AUTOSAR XML (schema 00046)
package /ComponentTypes
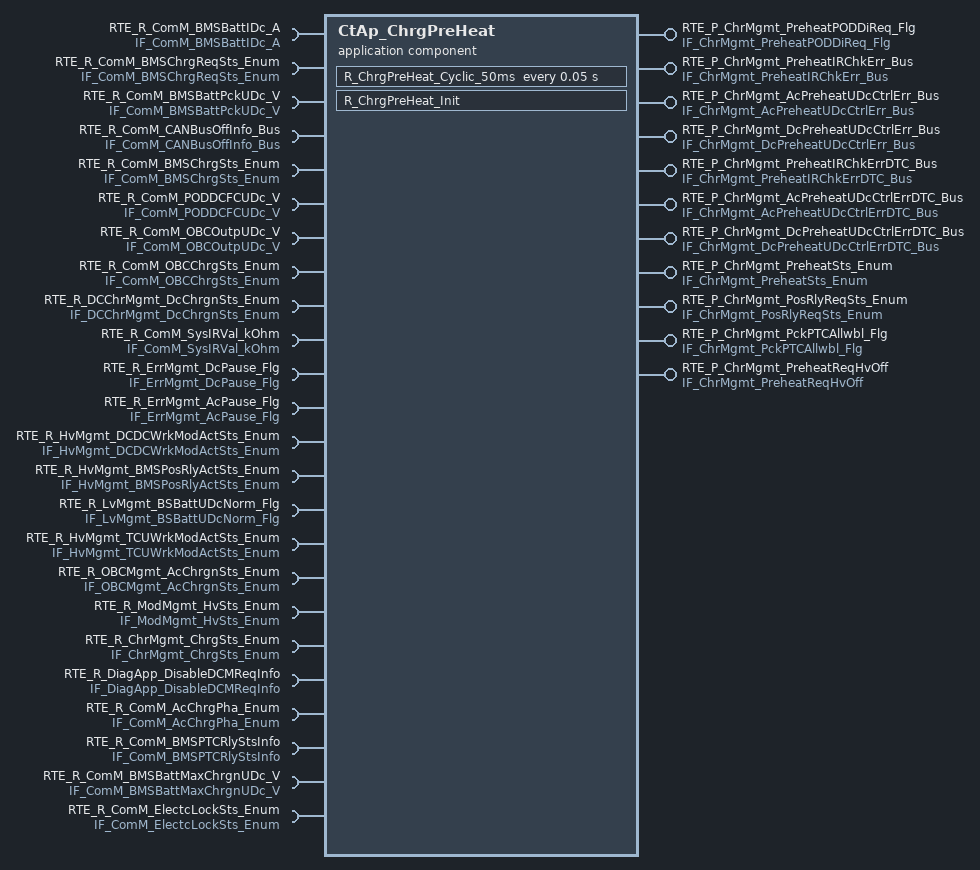
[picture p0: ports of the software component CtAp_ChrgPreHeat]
  application sw component type CtAp_ChrgPreHeat
    7 x provide port:
      RTE_P_ChrMgmt_PreheatPODDiReq_Flg: nonqueued-sender-com-spec{data-element=tec_ChrMgmt_PreheatPODDiReq_Flg, init-value=0}, provided-interface=IF_ChrMgmt_PreheatPODDiReq_Flg
      RTE_P_ChrMgmt_PreheatIRChkErr_Bus: nonqueued-sender-com-spec{data-element=tec_ChrMgmt_PreheatIRChkErr_Bus, init-value=fields=[ChrMgmt_MonStatPreheatIRChkErr:0, ChrMgmt_MonResPreheatIRChkErr:0, ChrMgmt_ErrStatPreheatIRChkErr:0, ChrMgmt_ErrResPreheatIRChkErr:0]}, provided-interface=IF_ChrMgmt_PreheatIRChkErr_Bus
      RTE_P_ChrMgmt_AcPreheatUDcCtrlErr_Bus: nonqueued-sender-com-spec{data-element=tec_ChrMgmt_AcPreheatUDcCtrlErr_Bus, init-value=fields=[ChrMgmt_MonStatAcPreheatUDcCtrlErr:0, ChrMgmt_MonResAcPreheatUDcCtrlErr:0, ChrMgmt_ErrStatAcPreheatUDcCtrlErr:0, ChrMgmt_ErrResAcPreheatUDcCtrlErr:0]}, provided-interface=IF_ChrMgmt_AcPreheatUDcCtrlErr_Bus
      RTE_P_ChrMgmt_DcPreheatUDcCtrlErr_Bus: nonqueued-sender-com-spec{data-element=tec_ChrMgmt_DcPreheatUDcCtrlErr_Bus, init-value=fields=[ChrMgmt_MonStatDcPreheatUDcCtrlErr:0, ChrMgmt_MonResDcPreheatUDcCtrlErr:0, ChrMgmt_ErrStatDcPreheatUDcCtrlErr:0, ChrMgmt_ErrResDcPreheatUDcCtrlErr:0]}, provided-interface=IF_ChrMgmt_DcPreheatUDcCtrlErr_Bus
      RTE_P_ChrMgmt_PreheatIRChkErrDTC_Bus: nonqueued-sender-com-spec{data-element=tec_ChrMgmt_PreheatIRChkErrDTC_Bus, init-value=fields=[ChrMgmt_MonStatPreheatIRChkErrDTC:0, ChrMgmt_MonResPreheatIRChkErrDTC:0, ChrMgmt_ErrStatPreheatIRChkErrDTC:0, ChrMgmt_ErrResPreheatIRChkErrDTC:0]}, provided-interface=IF_ChrMgmt_PreheatIRChkErrDTC_Bus
      RTE_P_ChrMgmt_AcPreheatUDcCtrlErrDTC_Bus: nonqueued-sender-com-spec{data-element=tec_ChrMgmt_AcPreheatUDcCtrlErrDTC_Bus, init-value=fields=[ChrMgmt_MonStatAcPreheatUDcCtrlErrDTC:0, ChrMgmt_MonResAcPreheatUDcCtrlErrDTC:0, ChrMgmt_ErrStatAcPreheatUDcCtrlErrDTC:0, ChrMgmt_ErrResAcPreheatUDcCtrlErrDTC:0]}, provided-interface=IF_ChrMgmt_AcPreheatUDcCtrlErrDTC_Bus
      RTE_P_ChrMgmt_DcPreheatUDcCtrlErrDTC_Bus: nonqueued-sender-com-spec{data-element=tec_ChrMgmt_DcPreheatUDcCtrlErrDTC_Bus, init-value=fields=[ChrMgmt_MonStatDcPreheatUDcCtrlErrDTC:0, ChrMgmt_MonResDcPreheatUDcCtrlErrDTC:0, ChrMgmt_ErrStatDcPreheatUDcCtrlErrDTC:0, ChrMgmt_ErrResDcPreheatUDcCtrlErrDTC:0]}, provided-interface=IF_ChrMgmt_DcPreheatUDcCtrlErrDTC_Bus
    18 x require port:
      RTE_R_ComM_BMSBattIDc_A: nonqueued-receiver-com-spec{data-element=tec_ComM_BMSBattIDc_A, filter=data-filter-type=ALWAYS, init-value=0}, required-interface=IF_ComM_BMSBattIDc_A
      RTE_R_ComM_BMSChrgReqSts_Enum: nonqueued-receiver-com-spec{data-element=tec_ComM_BMSChrgReqSts_Enum, filter=data-filter-type=ALWAYS, init-value=0}, required-interface=IF_ComM_BMSChrgReqSts_Enum
      RTE_R_ComM_BMSBattPckUDc_V: nonqueued-receiver-com-spec{data-element=tec_ComM_BMSBattPckUDc_V, filter=data-filter-type=ALWAYS, init-value=0}, required-interface=IF_ComM_BMSBattPckUDc_V
      RTE_R_ComM_CANBusOffInfo_Bus: required-interface=IF_ComM_CANBusOffInfo_Bus
        required-com-specs:
          data-element=tec_ComM_EPTCANBusOffInfo_Bus, filter=data-filter-type=ALWAYS, init-value=fields=[ComM_MonStatEPTCANBusOffInfo:0, ComM_MonResEPTCANBusOffInfo:0, ComM_ErrStatEPTCANBusOffInfo:0, ComM_ErrResEPTCANBusOffInfo:0]
          data-element=tec_ComM_CHCANBusOffInfo_Bus, filter=data-filter-type=ALWAYS, init-value=fields=[ComM_MonStatCHCANBusOffInfo:0, ComM_MonResCHCANBusOffInfo:0, ComM_ErrStatCHCANBusOffInfo:0, ComM_ErrResCHCANBusOffInfo:0]
          data-element=tec_ComM_EPTCANBusOffDTCInfo_Bus, filter=data-filter-type=ALWAYS, init-value=fields=[ComM_MonStatEPTCANBusOffDTCInfo:0, ComM_MonResEPTCANBusOffDTCInfo:0, ComM_ErrStatEPTCANBusOffDTCInfo:0, ComM_ErrResEPTCANBusOffDTCInfo:0]
          data-element=tec_ComM_CHCANBusOffDTCInfo_Bus, filter=data-filter-type=ALWAYS, init-value=fields=[ComM_MonStatCHCANBusOffDTCInfo:0, ComM_MonResCHCANBusOffDTCInfo:0, ComM_ErrStatCHCANBusOffDTCInfo:0, ComM_ErrResCHCANBusOffDTCInfo:0]
          data-element=tec_ComM_DCCANBusOffDTCInfo_Bus, init-value=fields=[ComM_MonStatDCCANDTCBusOffInfo:0, ComM_MonResDCCANDTCBusOffInfo:0, ComM_ErrStatDCCANDTCBusOffInfo:0, ComM_ErrResDCCANDTCBusOffInfo:0]
          data-element=tec_ComM_DCCANBusOffInfo_Bus, init-value=fields=[ComM_MonStatDCCANBusOffInfo:0, ComM_MonResDCCANBusOffInfo:0, ComM_ErrStatDCCANBusOffInfo:0, ComM_ErrResDCCANBusOffInfo:0]
      RTE_R_ComM_BMSChrgSts_Enum: nonqueued-receiver-com-spec{data-element=tec_ComM_BMSChrgSts_Enum, filter=data-filter-type=ALWAYS, init-value=0}, required-interface=IF_ComM_BMSChrgSts_Enum
      RTE_R_ComM_PODDCFCUDc_V: nonqueued-receiver-com-spec{data-element=tec_ComM_PODDCFCUDc_V, filter=data-filter-type=ALWAYS, init-value=0}, required-interface=IF_ComM_PODDCFCUDc_V
      RTE_R_ComM_OBCOutpUDc_V: nonqueued-receiver-com-spec{data-element=tec_ComM_OBCOutpUDc_V, filter=data-filter-type=ALWAYS, init-value=0}, required-interface=IF_ComM_OBCOutpUDc_V
      RTE_R_ComM_OBCChrgSts_Enum: nonqueued-receiver-com-spec{data-element=tec_ComM_OBCChrgSts_Enum, filter=data-filter-type=ALWAYS, init-value=0}, required-interface=IF_ComM_OBCChrgSts_Enum
      RTE_R_DCChrMgmt_DcChrgnSts_Enum: nonqueued-receiver-com-spec{data-element=tec_DCChrMgmt_DcChrgnSts_Enum, filter=data-filter-type=ALWAYS, init-value=0}, required-interface=IF_DCChrMgmt_DcChrgnSts_Enum
      RTE_R_ComM_SysIRVal_kOhm: nonqueued-receiver-com-spec{data-element=tec_ComM_SysIRVal_kOhm, filter=data-filter-type=ALWAYS, init-value=0}, required-interface=IF_ComM_SysIRVal_kOhm
      RTE_R_ErrMgmt_DcPause_Flg: nonqueued-receiver-com-spec{data-element=tec_ErrMgmt_DcPause_Flg, filter=data-filter-type=ALWAYS, init-value=0}, required-interface=IF_ErrMgmt_DcPause_Flg
      RTE_R_ErrMgmt_AcPause_Flg: nonqueued-receiver-com-spec{data-element=tec_ErrMgmt_AcPause_Flg, filter=data-filter-type=ALWAYS, init-value=0}, required-interface=IF_ErrMgmt_AcPause_Flg
      RTE_R_HvMgmt_DCDCWrkModActSts_Enum: nonqueued-receiver-com-spec{data-element=tec_HvMgmt_DCDCWrkModActSts_Enum, filter=data-filter-type=ALWAYS, init-value=0}, required-interface=IF_HvMgmt_DCDCWrkModActSts_Enum
      RTE_R_HvMgmt_BMSPosRlyActSts_Enum: nonqueued-receiver-com-spec{data-element=tec_HvMgmt_BMSPosRlyActSts_Enum, filter=data-filter-type=ALWAYS, init-value=0}, required-interface=IF_HvMgmt_BMSPosRlyActSts_Enum
      RTE_R_LvMgmt_BSBattUDcNorm_Flg: nonqueued-receiver-com-spec{data-element=tec_LvMgmt_BSBattUDcNorm_Flg, filter=data-filter-type=ALWAYS, init-value=0}, required-interface=IF_LvMgmt_BSBattUDcNorm_Flg
      RTE_R_HvMgmt_TCUWrkModActSts_Enum: nonqueued-receiver-com-spec{data-element=tec_HvMgmt_TCUWrkModActSts_Enum, filter=data-filter-type=ALWAYS, init-value=0}, required-interface=IF_HvMgmt_TCUWrkModActSts_Enum
      RTE_R_OBCMgmt_AcChrgnSts_Enum: nonqueued-receiver-com-spec{data-element=tec_OBCMgmt_AcChrgnSts_Enum, filter=data-filter-type=ALWAYS, init-value=0}, required-interface=IF_OBCMgmt_AcChrgnSts_Enum
      RTE_R_ModMgmt_HvSts_Enum: nonqueued-receiver-com-spec{data-element=tec_ModMgmt_HvSts_Enum, filter=data-filter-type=ALWAYS, init-value=0}, required-interface=IF_ModMgmt_HvSts_Enum
    provide port RTE_P_ChrMgmt_PreheatSts_Enum: nonqueued-sender-com-spec{data-element=tec_ChrMgmt_PreheatSts_Enum, init-value=0}, provided-interface=IF_ChrMgmt_PreheatSts_Enum
    require port RTE_R_ChrMgmt_ChrgSts_Enum: nonqueued-receiver-com-spec{data-element=tec_ChrMgmt_ChrgSts_Enum, filter=data-filter-type=ALWAYS, init-value=0}, required-interface=IF_ChrMgmt_ChrgSts_Enum
    require port RTE_R_DiagApp_DisableDCMReqInfo: nonqueued-receiver-com-spec{data-element=tec_DiagApp_DisableDCMReqInfo, filter=data-filter-type=ALWAYS, init-value=0}, required-interface=IF_DiagApp_DisableDCMReqInfo
    provide port RTE_P_ChrMgmt_PosRlyReqSts_Enum: nonqueued-sender-com-spec{data-element=tec_ChrMgmt_PosRlyReqSts_Enum, init-value=0}, provided-interface=IF_ChrMgmt_PosRlyReqSts_Enum
    provide port RTE_P_ChrMgmt_PckPTCAllwbl_Flg: nonqueued-sender-com-spec{data-element=tec_ChrMgmt_PckPTCAllwbl_Flg, init-value=0}, provided-interface=IF_ChrMgmt_PckPTCAllwbl_Flg
    require port RTE_R_ComM_AcChrgPha_Enum: nonqueued-receiver-com-spec{data-element=tec_ComM_AcChrgPha_Enum, filter=data-filter-type=ALWAYS, init-value=0}, required-interface=IF_ComM_AcChrgPha_Enum
    provide port RTE_P_ChrMgmt_PreheatReqHvOff: nonqueued-sender-com-spec{data-element=tec_ChrMgmt_PreheatReqHvOff, init-value=0}, provided-interface=IF_ChrMgmt_PreheatReqHvOff
    require port RTE_R_ComM_BMSPTCRlyStsInfo: nonqueued-receiver-com-spec{data-element=tec_ComM_BMSPTCRlyStsInfo, filter=data-filter-type=ALWAYS, init-value=0}, required-interface=IF_ComM_BMSPTCRlyStsInfo
    require port RTE_R_ComM_BMSBattMaxChrgnUDc_V: nonqueued-receiver-com-spec{data-element=tec_ComM_BMSBattMaxChrgnUDc_V, filter=data-filter-type=ALWAYS, init-value=0}, required-interface=IF_ComM_BMSBattMaxChrgnUDc_V
    require port RTE_R_ComM_ElectcLockSts_Enum: nonqueued-receiver-com-spec{data-element=tec_ComM_ElectcLockSts_Enum, filter=data-filter-type=ALWAYS, init-value=0}, required-interface=IF_ComM_ElectcLockSts_Enum
    behavior CtAp_ChrgPreHeat_InternalBehavior
      timing event TMT_R_ChrgPreHeat_Cyclic_50ms: start-on-event=R_ChrgPreHeat_Cyclic_50ms, period=0.05
      init event CtAp_ChrgPreHeat_InitEvent: start-on-event=R_ChrgPreHeat_Init
      runnable R_ChrgPreHeat_Cyclic_50ms
        data-receive-point-by-arguments:
          24 x access:
            REC_RTE_R_ChrMgmt_ChrgSts_Enum_tec_ChrMgmt_ChrgSts_Enum: accessed-variable=RTE_R_ChrMgmt_ChrgSts_Enum.tec_ChrMgmt_ChrgSts_Enum
            REC_RTE_R_ComM_BMSBattIDc_A_tec_ComM_BMSBattIDc_A: accessed-variable=RTE_R_ComM_BMSBattIDc_A.tec_ComM_BMSBattIDc_A
            REC_RTE_R_ComM_BMSBattPckUDc_V_tec_ComM_BMSBattPckUDc_V: accessed-variable=RTE_R_ComM_BMSBattPckUDc_V.tec_ComM_BMSBattPckUDc_V
            REC_RTE_R_ComM_BMSChrgReqSts_Enum_tec_ComM_BMSChrgReqSts_Enum: accessed-variable=RTE_R_ComM_BMSChrgReqSts_Enum.tec_ComM_BMSChrgReqSts_Enum
            REC_RTE_R_ComM_BMSChrgSts_Enum_tec_ComM_BMSChrgSts_Enum: accessed-variable=RTE_R_ComM_BMSChrgSts_Enum.tec_ComM_BMSChrgSts_Enum
            REC_RTE_R_ComM_CANBusOffInfo_Bus_tec_ComM_EPTCANBusOffInfo_Bus: accessed-variable=RTE_R_ComM_CANBusOffInfo_Bus.tec_ComM_EPTCANBusOffInfo_Bus
            REC_RTE_R_ComM_OBCChrgSts_Enum_tec_ComM_OBCChrgSts_Enum: accessed-variable=RTE_R_ComM_OBCChrgSts_Enum.tec_ComM_OBCChrgSts_Enum
            REC_RTE_R_ComM_OBCOutpUDc_V_tec_ComM_OBCOutpUDc_V: accessed-variable=RTE_R_ComM_OBCOutpUDc_V.tec_ComM_OBCOutpUDc_V
            REC_RTE_R_ComM_PODDCFCUDc_V_tec_ComM_PODDCFCUDc_V: accessed-variable=RTE_R_ComM_PODDCFCUDc_V.tec_ComM_PODDCFCUDc_V
            REC_RTE_R_ComM_SysIRVal_kOhm_tec_ComM_SysIRVal_kOhm: accessed-variable=RTE_R_ComM_SysIRVal_kOhm.tec_ComM_SysIRVal_kOhm
            REC_RTE_R_DCChrMgmt_DcChrgnSts_Enum_tec_DCChrMgmt_DcChrgnSts_Enum: accessed-variable=RTE_R_DCChrMgmt_DcChrgnSts_Enum.tec_DCChrMgmt_DcChrgnSts_Enum
            REC_RTE_R_ErrMgmt_AcPause_Flg_tec_ErrMgmt_AcPause_Flg: accessed-variable=RTE_R_ErrMgmt_AcPause_Flg.tec_ErrMgmt_AcPause_Flg
            REC_RTE_R_ErrMgmt_DcPause_Flg_tec_ErrMgmt_DcPause_Flg: accessed-variable=RTE_R_ErrMgmt_DcPause_Flg.tec_ErrMgmt_DcPause_Flg
            REC_RTE_R_HvMgmt_BMSPosRlyActSts_Enum_tec_HvMgmt_BMSPosRlyActSts_Enum: accessed-variable=RTE_R_HvMgmt_BMSPosRlyActSts_Enum.tec_HvMgmt_BMSPosRlyActSts_Enum
            REC_RTE_R_HvMgmt_DCDCWrkModActSts_Enum_tec_HvMgmt_DCDCWrkModActSts_Enum: accessed-variable=RTE_R_HvMgmt_DCDCWrkModActSts_Enum.tec_HvMgmt_DCDCWrkModActSts_Enum
            REC_RTE_R_HvMgmt_TCUWrkModActSts_Enum_tec_HvMgmt_TCUWrkModActSts_Enum: accessed-variable=RTE_R_HvMgmt_TCUWrkModActSts_Enum.tec_HvMgmt_TCUWrkModActSts_Enum
            REC_RTE_R_LvMgmt_BSBattUDcNorm_Flg_tec_LvMgmt_BSBattUDcNorm_Flg: accessed-variable=RTE_R_LvMgmt_BSBattUDcNorm_Flg.tec_LvMgmt_BSBattUDcNorm_Flg
            REC_RTE_R_ModMgmt_HvSts_Enum_tec_ModMgmt_HvSts_Enum: accessed-variable=RTE_R_ModMgmt_HvSts_Enum.tec_ModMgmt_HvSts_Enum
            REC_RTE_R_OBCMgmt_AcChrgnSts_Enum_tec_OBCMgmt_AcChrgnSts_Enum: accessed-variable=RTE_R_OBCMgmt_AcChrgnSts_Enum.tec_OBCMgmt_AcChrgnSts_Enum
            REC_RTE_R_DiagApp_DisableDCMReqInfo_tec_DiagApp_DisableDCMReqInfo: accessed-variable=RTE_R_DiagApp_DisableDCMReqInfo.tec_DiagApp_DisableDCMReqInfo
            REC_RTE_R_ComM_AcChrgPha_Enum_tec_ComM_AcChrgPha_Enum: accessed-variable=RTE_R_ComM_AcChrgPha_Enum.tec_ComM_AcChrgPha_Enum
            REC_RTE_R_ComM_BMSPTCRlyStsInfo_tec_ComM_BMSPTCRlyStsInfo: accessed-variable=RTE_R_ComM_BMSPTCRlyStsInfo.tec_ComM_BMSPTCRlyStsInfo
            REC_RTE_R_ComM_BMSBattMaxChrgnUDc_V_tec_ComM_BMSBattMaxChrgnUDc_V: accessed-variable=RTE_R_ComM_BMSBattMaxChrgnUDc_V.tec_ComM_BMSBattMaxChrgnUDc_V
            REC_RTE_R_ComM_ElectcLockSts_Enum_tec_ComM_ElectcLockSts_Enum: accessed-variable=RTE_R_ComM_ElectcLockSts_Enum.tec_ComM_ElectcLockSts_Enum
        data-send-points:
          11 x access:
            SEND_RTE_P_ChrMgmt_AcPreheatUDcCtrlErrDTC_Bus_tec_ChrMgmt_AcPreheatUDcCtrlErrDTC_Bus: accessed-variable=RTE_P_ChrMgmt_AcPreheatUDcCtrlErrDTC_Bus.tec_ChrMgmt_AcPreheatUDcCtrlErrDTC_Bus
            SEND_RTE_P_ChrMgmt_AcPreheatUDcCtrlErr_Bus_tec_ChrMgmt_AcPreheatUDcCtrlErr_Bus: accessed-variable=RTE_P_ChrMgmt_AcPreheatUDcCtrlErr_Bus.tec_ChrMgmt_AcPreheatUDcCtrlErr_Bus
            SEND_RTE_P_ChrMgmt_DcPreheatUDcCtrlErrDTC_Bus_tec_ChrMgmt_DcPreheatUDcCtrlErrDTC_Bus: accessed-variable=RTE_P_ChrMgmt_DcPreheatUDcCtrlErrDTC_Bus.tec_ChrMgmt_DcPreheatUDcCtrlErrDTC_Bus
            SEND_RTE_P_ChrMgmt_DcPreheatUDcCtrlErr_Bus_tec_ChrMgmt_DcPreheatUDcCtrlErr_Bus: accessed-variable=RTE_P_ChrMgmt_DcPreheatUDcCtrlErr_Bus.tec_ChrMgmt_DcPreheatUDcCtrlErr_Bus
            SEND_RTE_P_ChrMgmt_PreheatIRChkErrDTC_Bus_tec_ChrMgmt_PreheatIRChkErrDTC_Bus: accessed-variable=RTE_P_ChrMgmt_PreheatIRChkErrDTC_Bus.tec_ChrMgmt_PreheatIRChkErrDTC_Bus
            SEND_RTE_P_ChrMgmt_PreheatIRChkErr_Bus_tec_ChrMgmt_PreheatIRChkErr_Bus: accessed-variable=RTE_P_ChrMgmt_PreheatIRChkErr_Bus.tec_ChrMgmt_PreheatIRChkErr_Bus
            SEND_RTE_P_ChrMgmt_PreheatPODDiReq_Flg_tec_ChrMgmt_PreheatPODDiReq_Flg: accessed-variable=RTE_P_ChrMgmt_PreheatPODDiReq_Flg.tec_ChrMgmt_PreheatPODDiReq_Flg
            SEND_RTE_P_ChrMgmt_PreheatSts_Enum_tec_ChrMgmt_PreheatSts_Enum: accessed-variable=RTE_P_ChrMgmt_PreheatSts_Enum.tec_ChrMgmt_PreheatSts_Enum
            SEND_RTE_P_ChrMgmt_PckPTCAllwbl_Flg_tec_ChrMgmt_PckPTCAllwbl_Flg: accessed-variable=RTE_P_ChrMgmt_PckPTCAllwbl_Flg.tec_ChrMgmt_PckPTCAllwbl_Flg
            SEND_RTE_P_ChrMgmt_PosRlyReqSts_Enum_tec_ChrMgmt_PosRlyReqSts_Enum: accessed-variable=RTE_P_ChrMgmt_PosRlyReqSts_Enum.tec_ChrMgmt_PosRlyReqSts_Enum
            SEND_RTE_P_ChrMgmt_PreheatReqHvOff_tec_ChrMgmt_PreheatReqHvOff: accessed-variable=RTE_P_ChrMgmt_PreheatReqHvOff.tec_ChrMgmt_PreheatReqHvOff
      runnable R_ChrgPreHeat_Init
  swc implementation CtAp_ChrgPreHeat_Implementation: behavior=CtAp_ChrgPreHeat_InternalBehavior
